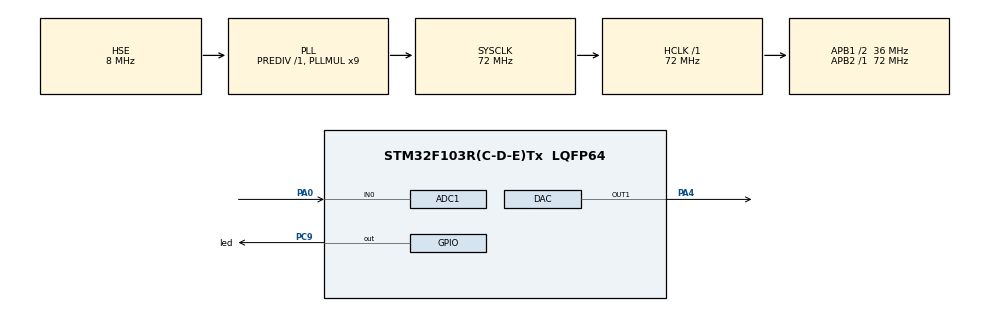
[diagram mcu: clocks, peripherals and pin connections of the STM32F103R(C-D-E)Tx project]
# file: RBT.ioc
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ADC1.Channel-0\#ChannelRegularConversion=ADC_CHANNEL_0
ADC1.ContinuousConvMode=ENABLE
ADC1.NbrOfConversionFlag=1
ADC1.Rank-0\#ChannelRegularConversion=1
ADC1.SamplingTime-0\#ChannelRegularConversion=ADC_SAMPLETIME_1CYCLE_5
ADC1.master=1
Dma.ADC1.0.Direction=DMA_PERIPH_TO_MEMORY
Dma.ADC1.0.Instance=DMA1_Channel1
Dma.ADC1.0.MemDataAlignment=DMA_MDATAALIGN_WORD
Dma.ADC1.0.MemInc=DMA_MINC_ENABLE
Dma.ADC1.0.Mode=DMA_CIRCULAR
Dma.ADC1.0.PeriphDataAlignment=DMA_PDATAALIGN_WORD
Dma.ADC1.0.PeriphInc=DMA_PINC_DISABLE
Dma.ADC1.0.Priority=DMA_PRIORITY_VERY_HIGH
Dma.Request0=ADC1
Mcu.Family=STM32F1
Mcu.Name=STM32F103R(C-D-E)Tx
Mcu.Package=LQFP64
NVIC.ADC1_2_IRQn=true\:0\:0\:false\:false\:true
NVIC.DMA1_Channel1_IRQn=true\:0\:0\:false\:false\:true
NVIC.PriorityGroup=NVIC_PRIORITYGROUP_4
NVIC.TIM1_BRK_IRQn=true\:0\:0\:false\:false\:true
NVIC.TIM1_CC_IRQn=true\:0\:0\:false\:false\:true
NVIC.TIM1_TRG_COM_IRQn=true\:0\:0\:false\:false\:true
NVIC.TIM1_UP_IRQn=true\:0\:0\:false\:false\:true
PA0-WKUP.Signal=ADCx_IN0
PA4.Signal=COMP_DAC1_group
PC9.GPIO_Label=led
PC9.Signal=GPIO_Output
PD0-OSC_IN.Mode=HSE-External-Oscillator
PD0-OSC_IN.Signal=RCC_OSC_IN
PD1-OSC_OUT.Mode=HSE-External-Oscillator
PD1-OSC_OUT.Signal=RCC_OSC_OUT
ProjectManager.HeapSize=0x200
ProjectManager.StackSize=0x400
ProjectManager.TargetToolchain=SW4STM32
RCC.ADCPresc=RCC_ADCPCLK2_DIV6
RCC.AHBFreq_Value=72000000
RCC.APB1CLKDivider=RCC_HCLK_DIV2
RCC.APB1Freq_Value=36000000
RCC.APB1TimFreq_Value=72000000
RCC.APB2Freq_Value=72000000
RCC.APB2TimFreq_Value=72000000
RCC.EnbaleCSS=true
RCC.HCLKFreq_Value=72000000
RCC.HSIState=RCC_HSI_ON
RCC.PLLMUL=RCC_PLL_MUL9
RCC.PLLSourceVirtual=RCC_PLLSOURCE_HSE
RCC.SYSCLKFreq_VALUE=72000000
RCC.SYSCLKSource=RCC_SYSCLKSOURCE_PLLCLK
RCC.USBFreq_Value=72000000
SH.ADCx_IN0.0=ADC1_IN0,IN0
SH.COMP_DAC1_group.0=DAC_OUT1,DAC_OUT1
TIM1.Period=719
VP_SYS_VS_ND.Mode=No_Debug
VP_TIM1_VS_ClockSourceINT.Mode=Internal
board=RBT

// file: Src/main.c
/**
  ******************************************************************************
  * File Name          : main.c
  * Description        : Main program body
  ******************************************************************************
  *
  * COPYRIGHT(c) 2016 STMicroelectronics
  *
  * Redistribution and use in source and binary forms, with or without modification,
  * are permitted provided that the following conditions are met:
  *   1. Redistributions of source code must retain the above copyright notice,
  *      this list of conditions and the following disclaimer.
  *   2. Redistributions in binary form must reproduce the above copyright notice,
  *      this list of conditions and the following disclaimer in the documentation
  *      and/or other materials provided with the distribution.
  *   3. Neither the name of STMicroelectronics nor the names of its contributors
  *      may be used to endorse or promote products derived from this software
  *      without specific prior written permission.
  *
  * THIS SOFTWARE IS PROVIDED BY THE COPYRIGHT HOLDERS AND CONTRIBUTORS "AS IS"
  * AND ANY EXPRESS OR IMPLIED WARRANTIES, INCLUDING, BUT NOT LIMITED TO, THE
  * IMPLIED WARRANTIES OF MERCHANTABILITY AND FITNESS FOR A PARTICULAR PURPOSE ARE
  * DISCLAIMED. IN NO EVENT SHALL THE COPYRIGHT HOLDER OR CONTRIBUTORS BE LIABLE
  * FOR ANY DIRECT, INDIRECT, INCIDENTAL, SPECIAL, EXEMPLARY, OR CONSEQUENTIAL
  * DAMAGES (INCLUDING, BUT NOT LIMITED TO, PROCUREMENT OF SUBSTITUTE GOODS OR
  * SERVICES; LOSS OF USE, DATA, OR PROFITS; OR BUSINESS INTERRUPTION) HOWEVER
  * CAUSED AND ON ANY THEORY OF LIABILITY, WHETHER IN CONTRACT, STRICT LIABILITY,
  * OR TORT (INCLUDING NEGLIGENCE OR OTHERWISE) ARISING IN ANY WAY OUT OF THE USE
  * OF THIS SOFTWARE, EVEN IF ADVISED OF THE POSSIBILITY OF SUCH DAMAGE.
  *
  ******************************************************************************
  */
#include "stm32f1xx_hal.h"

ADC_HandleTypeDef hadc1;
DMA_HandleTypeDef hdma_adc1;

DAC_HandleTypeDef hdac;

TIM_HandleTypeDef htim1;

/* USER CODE BEGIN PV */
/* Private variables ---------------------------------------------------------*/

/* USER CODE END PV */

void SystemClock_Config(void);
void Error_Handler(void);
static void MX_GPIO_Init(void);
static void MX_DMA_Init(void);
static void MX_ADC1_Init(void);
static void MX_DAC_Init(void);
static void MX_TIM1_Init(void);

/* USER CODE BEGIN PFP */
/* Private function prototypes -----------------------------------------------*/

/* USER CODE END PFP */

/* USER CODE BEGIN 0 */
uint32_t dac_value;
/* USER CODE END 0 */

int main(void)
{

  /* MCU Configuration----------------------------------------------------------*/

  /* Reset of all peripherals, Initializes the Flash interface and the Systick. */
  HAL_Init();

  /* Configure the system clock */
  SystemClock_Config();

  /* Initialize all configured peripherals */
  MX_GPIO_Init();
  MX_DMA_Init();
  MX_ADC1_Init();
  MX_DAC_Init();
  MX_TIM1_Init();

  /* USER CODE BEGIN 2 */
  HAL_DAC_Start(&hdac,DAC_CHANNEL_1);
  /* USER CODE END 2 */

  /* Infinite loop */
  while (1)
  {

  /* USER CODE BEGIN 3 */
	  HAL_DAC_SetValue(&hdac,DAC_CHANNEL_1,DAC_ALIGN_12B_R,dac_value);
	  HAL_Delay(200);
	  dac_value++;
  }
  /* USER CODE END 3 */

}

/** System Clock Configuration
*/
void SystemClock_Config(void)
{

  RCC_OscInitTypeDef RCC_OscInitStruct;
  RCC_ClkInitTypeDef RCC_ClkInitStruct;
  RCC_PeriphCLKInitTypeDef PeriphClkInit;

  RCC_OscInitStruct.OscillatorType = RCC_OSCILLATORTYPE_HSE;
  RCC_OscInitStruct.HSEState = RCC_HSE_ON;
  RCC_OscInitStruct.HSEPredivValue = RCC_HSE_PREDIV_DIV1;
  RCC_OscInitStruct.PLL.PLLState = RCC_PLL_ON;
  RCC_OscInitStruct.PLL.PLLSource = RCC_PLLSOURCE_HSE;
  RCC_OscInitStruct.PLL.PLLMUL = RCC_PLL_MUL9;
  if (HAL_RCC_OscConfig(&RCC_OscInitStruct) != HAL_OK)
  {
    Error_Handler();
  }

  RCC_ClkInitStruct.ClockType = RCC_CLOCKTYPE_HCLK|RCC_CLOCKTYPE_SYSCLK
                              |RCC_CLOCKTYPE_PCLK1|RCC_CLOCKTYPE_PCLK2;
  RCC_ClkInitStruct.SYSCLKSource = RCC_SYSCLKSOURCE_PLLCLK;
  RCC_ClkInitStruct.AHBCLKDivider = RCC_SYSCLK_DIV1;
  RCC_ClkInitStruct.APB1CLKDivider = RCC_HCLK_DIV2;
  RCC_ClkInitStruct.APB2CLKDivider = RCC_HCLK_DIV1;
  if (HAL_RCC_ClockConfig(&RCC_ClkInitStruct, FLASH_LATENCY_2) != HAL_OK)
  {
    Error_Handler();
  }

  PeriphClkInit.PeriphClockSelection = RCC_PERIPHCLK_ADC;
  PeriphClkInit.AdcClockSelection = RCC_ADCPCLK2_DIV6;
  if (HAL_RCCEx_PeriphCLKConfig(&PeriphClkInit) != HAL_OK)
  {
    Error_Handler();
  }

  HAL_RCC_EnableCSS();

  HAL_SYSTICK_Config(HAL_RCC_GetHCLKFreq()/1000);

  HAL_SYSTICK_CLKSourceConfig(SYSTICK_CLKSOURCE_HCLK);

  /* SysTick_IRQn interrupt configuration */
  HAL_NVIC_SetPriority(SysTick_IRQn, 0, 0);
}

/* ADC1 init function */
static void MX_ADC1_Init(void)
{

  ADC_ChannelConfTypeDef sConfig;

    /**Common config
    */
  hadc1.Instance = ADC1;
  hadc1.Init.ScanConvMode = ADC_SCAN_DISABLE;
  hadc1.Init.ContinuousConvMode = ENABLE;
  hadc1.Init.DiscontinuousConvMode = DISABLE;
  hadc1.Init.ExternalTrigConv = ADC_SOFTWARE_START;
  hadc1.Init.DataAlign = ADC_DATAALIGN_RIGHT;
  hadc1.Init.NbrOfConversion = 1;
  if (HAL_ADC_Init(&hadc1) != HAL_OK)
  {
    Error_Handler();
  }

    /**Configure Regular Channel
    */
  sConfig.Channel = ADC_CHANNEL_0;
  sConfig.Rank = 1;
  sConfig.SamplingTime = ADC_SAMPLETIME_1CYCLE_5;
  if (HAL_ADC_ConfigChannel(&hadc1, &sConfig) != HAL_OK)
  {
    Error_Handler();
  }

}

/* DAC init function */
static void MX_DAC_Init(void)
{

  DAC_ChannelConfTypeDef sConfig;

    /**DAC Initialization
    */
  hdac.Instance = DAC;
  if (HAL_DAC_Init(&hdac) != HAL_OK)
  {
    Error_Handler();
  }

    /**DAC channel OUT1 config
    */
  sConfig.DAC_Trigger = DAC_TRIGGER_NONE;
  sConfig.DAC_OutputBuffer = DAC_OUTPUTBUFFER_ENABLE;
  if (HAL_DAC_ConfigChannel(&hdac, &sConfig, DAC_CHANNEL_1) != HAL_OK)
  {
    Error_Handler();
  }

}

/* TIM1 init function */
static void MX_TIM1_Init(void)
{

  TIM_ClockConfigTypeDef sClockSourceConfig;
  TIM_MasterConfigTypeDef sMasterConfig;

  htim1.Instance = TIM1;
  htim1.Init.Prescaler = 0;
  htim1.Init.CounterMode = TIM_COUNTERMODE_UP;
  htim1.Init.Period = 719;
  htim1.Init.ClockDivision = TIM_CLOCKDIVISION_DIV1;
  htim1.Init.RepetitionCounter = 0;
  if (HAL_TIM_Base_Init(&htim1) != HAL_OK)
  {
    Error_Handler();
  }

  sClockSourceConfig.ClockSource = TIM_CLOCKSOURCE_INTERNAL;
  if (HAL_TIM_ConfigClockSource(&htim1, &sClockSourceConfig) != HAL_OK)
  {
    Error_Handler();
  }

  sMasterConfig.MasterOutputTrigger = TIM_TRGO_RESET;
  sMasterConfig.MasterSlaveMode = TIM_MASTERSLAVEMODE_DISABLE;
  if (HAL_TIMEx_MasterConfigSynchronization(&htim1, &sMasterConfig) != HAL_OK)
  {
    Error_Handler();
  }

}

static void MX_DMA_Init(void)
{
  /* DMA controller clock enable */
  __HAL_RCC_DMA1_CLK_ENABLE();

  /* DMA interrupt init */
  /* DMA1_Channel1_IRQn interrupt configuration */
  HAL_NVIC_SetPriority(DMA1_Channel1_IRQn, 0, 0);
  HAL_NVIC_EnableIRQ(DMA1_Channel1_IRQn);

}

/** Configure pins as
        * Analog
        * Input
        * Output
        * EVENT_OUT
        * EXTI
*/
static void MX_GPIO_Init(void)
{

  GPIO_InitTypeDef GPIO_InitStruct;

  /* GPIO Ports Clock Enable */
  __HAL_RCC_GPIOD_CLK_ENABLE();
  __HAL_RCC_GPIOA_CLK_ENABLE();
  __HAL_RCC_GPIOC_CLK_ENABLE();

  /*Configure GPIO pin Output Level */
  HAL_GPIO_WritePin(led_GPIO_Port, led_Pin, GPIO_PIN_RESET);

  /*Configure GPIO pin : led_Pin */
  GPIO_InitStruct.Pin = led_Pin;
  GPIO_InitStruct.Mode = GPIO_MODE_OUTPUT_PP;
  GPIO_InitStruct.Speed = GPIO_SPEED_FREQ_LOW;
  HAL_GPIO_Init(led_GPIO_Port, &GPIO_InitStruct);

}

void Error_Handler(void)
{
  while(1)
  {
  }
}

/************************ (C) COPYRIGHT STMicroelectronics *****END OF FILE****/
